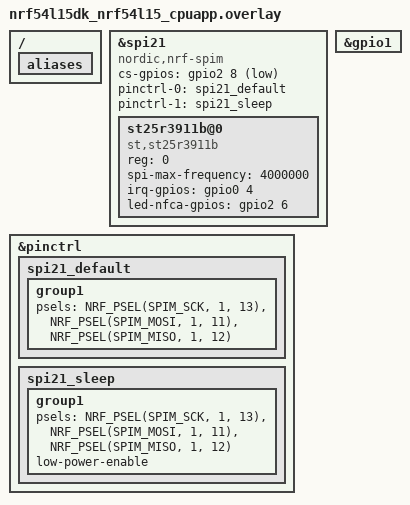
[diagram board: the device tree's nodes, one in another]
/{
	/* For convenience disable buttons for now to avoid a mess with interrupt and SCK pins. */
	/delete-node/ buttons;

	aliases {
		/delete-property/ sw0;
		/delete-property/ sw1;
		/delete-property/ sw2;
		/delete-property/ sw3;
	};
};

&spi21 {
	compatible = "nordic,nrf-spim";
	status = "okay";
	cs-gpios = <&gpio2 8 GPIO_ACTIVE_LOW>;

	pinctrl-0 = <&spi21_default>;
	pinctrl-1 = <&spi21_sleep>;
	pinctrl-names = "default", "sleep";
	st25r3911b@0 {
		compatible = "st,st25r3911b";
		reg = <0>;
		spi-max-frequency = <4000000>;
		irq-gpios = <&gpio0 4 GPIO_ACTIVE_HIGH>; /* Expropriate PIN 0.4 that is used for Button3. */
		led-nfca-gpios = <&gpio2 6 GPIO_ACTIVE_HIGH>;
	};
};

&pinctrl {
	spi21_default: spi21_default {
		group1 {
			psels = <NRF_PSEL(SPIM_SCK, 1, 13)>, /* Expropriate PIN 1.13 that is used for Button0. */
				<NRF_PSEL(SPIM_MOSI, 1, 11)>,
				<NRF_PSEL(SPIM_MISO, 1, 12)>;
		};
	};

	spi21_sleep: spi21_sleep {
		group1 {
			psels = <NRF_PSEL(SPIM_SCK, 1, 13)>,
				<NRF_PSEL(SPIM_MOSI, 1, 11)>,
				<NRF_PSEL(SPIM_MISO, 1, 12)>;
			low-power-enable;
		};
	};
};

&gpio1 {
	status = "okay";
};
